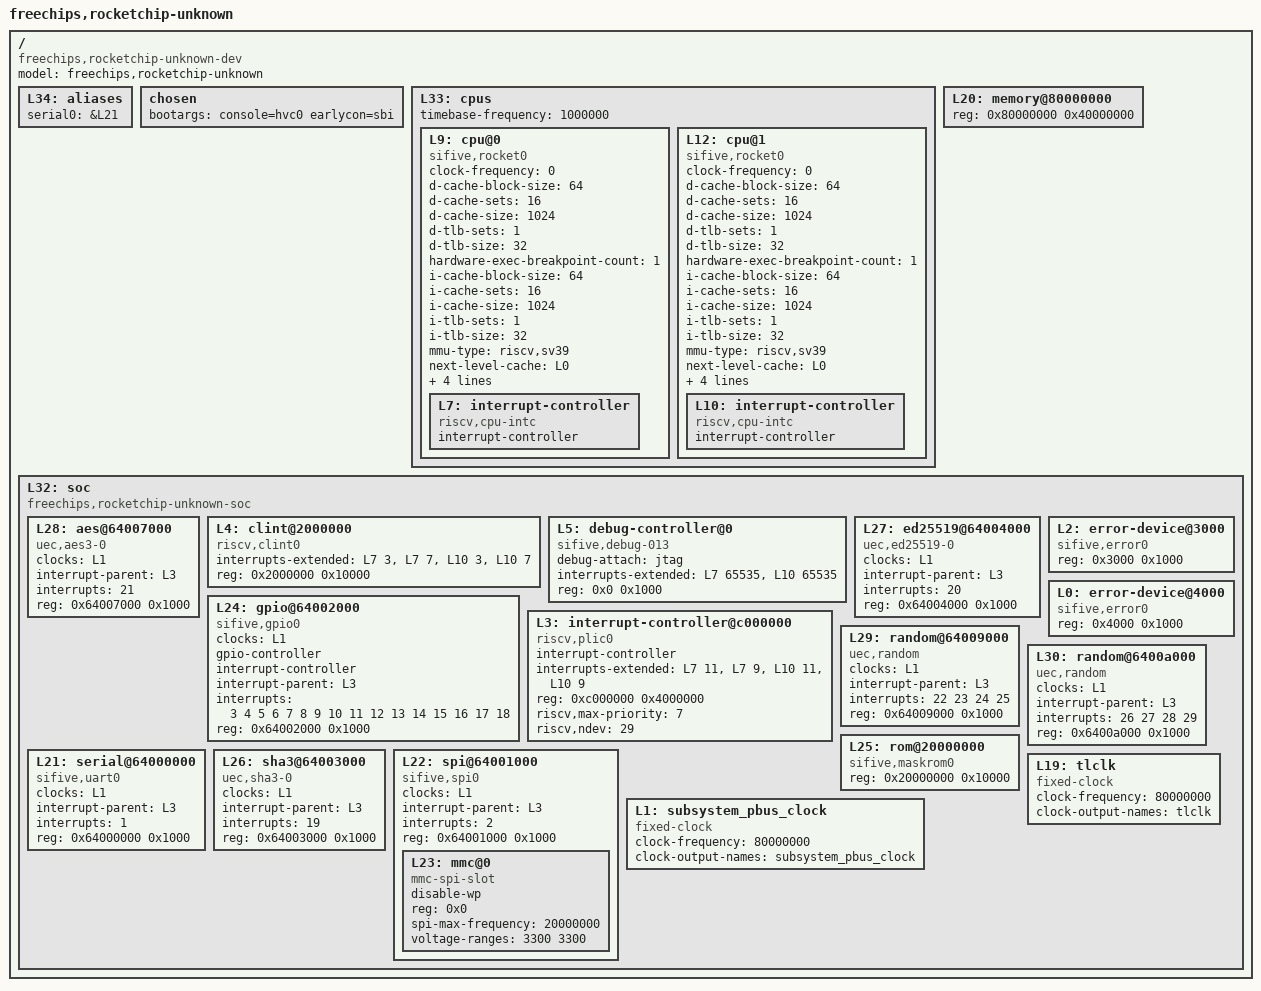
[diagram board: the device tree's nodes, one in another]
/dts-v1/;

/ {
	#address-cells = <1>;
	#size-cells = <1>;
	compatible = "freechips,rocketchip-unknown-dev";
	model = "freechips,rocketchip-unknown";
	L34: aliases {
		serial0 = &L21;
	};
	chosen {
    bootargs = "console=hvc0 earlycon=sbi";
	};
	L33: cpus {
		#address-cells = <1>;
		#size-cells = <0>;
		timebase-frequency = <1000000>;
		L9: cpu@0 {
			clock-frequency = <0>;
			compatible = "sifive,rocket0", "riscv";
			d-cache-block-size = <64>;
			d-cache-sets = <16>;
			d-cache-size = <1024>;
			d-tlb-sets = <1>;
			d-tlb-size = <32>;
			device_type = "cpu";
			hardware-exec-breakpoint-count = <1>;
			i-cache-block-size = <64>;
			i-cache-sets = <16>;
			i-cache-size = <1024>;
			i-tlb-sets = <1>;
			i-tlb-size = <32>;
			mmu-type = "riscv,sv39";
			next-level-cache = <&L0>;
			reg = <0x0>;
			riscv,isa = "rv64imafdc";
			riscv,pmpregions = <8>;
			status = "okay";
			tlb-split;
			L7: interrupt-controller {
				#interrupt-cells = <1>;
				compatible = "riscv,cpu-intc";
				interrupt-controller;
			};
		};
		L12: cpu@1 {
			clock-frequency = <0>;
			compatible = "sifive,rocket0", "riscv";
			d-cache-block-size = <64>;
			d-cache-sets = <16>;
			d-cache-size = <1024>;
			d-tlb-sets = <1>;
			d-tlb-size = <32>;
			device_type = "cpu";
			hardware-exec-breakpoint-count = <1>;
			i-cache-block-size = <64>;
			i-cache-sets = <16>;
			i-cache-size = <1024>;
			i-tlb-sets = <1>;
			i-tlb-size = <32>;
			mmu-type = "riscv,sv39";
			next-level-cache = <&L0>;
			reg = <0x1>;
			riscv,isa = "rv64imafdc";
			riscv,pmpregions = <8>;
			status = "okay";
			tlb-split;
			L10: interrupt-controller {
				#interrupt-cells = <1>;
				compatible = "riscv,cpu-intc";
				interrupt-controller;
			};
		};
	};
	L20: memory@80000000 {
		device_type = "memory";
		reg = <0x80000000 0x40000000>;
	};
	L32: soc {
		#address-cells = <1>;
		#size-cells = <1>;
		compatible = "freechips,rocketchip-unknown-soc", "simple-bus";
		ranges;
		L28: aes@64007000 {
			clocks = <&L1>;
			compatible = "uec,aes3-0";
			interrupt-parent = <&L3>;
			interrupts = <21>;
			reg = <0x64007000 0x1000>;
			reg-names = "control";
		};
		L4: clint@2000000 {
			compatible = "riscv,clint0";
			interrupts-extended = <&L7 3 &L7 7 &L10 3 &L10 7>;
			reg = <0x2000000 0x10000>;
			reg-names = "control";
		};
		L5: debug-controller@0 {
			compatible = "sifive,debug-013", "riscv,debug-013";
			debug-attach = "jtag";
			interrupts-extended = <&L7 65535 &L10 65535>;
			reg = <0x0 0x1000>;
			reg-names = "control";
		};
		L27: ed25519@64004000 {
			clocks = <&L1>;
			compatible = "uec,ed25519-0";
			interrupt-parent = <&L3>;
			interrupts = <20>;
			reg = <0x64004000 0x1000>;
			reg-names = "control";
		};
		L2: error-device@3000 {
			compatible = "sifive,error0";
			reg = <0x3000 0x1000>;
		};
		L0: error-device@4000 {
			compatible = "sifive,error0";
			reg = <0x4000 0x1000>;
		};
		L24: gpio@64002000 {
			#gpio-cells = <2>;
			#interrupt-cells = <2>;
			clocks = <&L1>;
			compatible = "sifive,gpio0", "sifive,gpio1";
			gpio-controller;
			interrupt-controller;
			interrupt-parent = <&L3>;
			interrupts = <3 4 5 6 7 8 9 10 11 12 13 14 15 16 17 18>;
			reg = <0x64002000 0x1000>;
			reg-names = "control";
		};
		L3: interrupt-controller@c000000 {
			#interrupt-cells = <1>;
			compatible = "riscv,plic0";
			interrupt-controller;
			interrupts-extended = <&L7 11 &L7 9 &L10 11 &L10 9>;
			reg = <0xc000000 0x4000000>;
			reg-names = "control";
			riscv,max-priority = <7>;
			riscv,ndev = <29>;
		};
		L29: random@64009000 {
			clocks = <&L1>;
			compatible = "uec,random";
			interrupt-parent = <&L3>;
			interrupts = <22 23 24 25>;
			reg = <0x64009000 0x1000>;
			reg-names = "control";
		};
		L30: random@6400a000 {
			clocks = <&L1>;
			compatible = "uec,random";
			interrupt-parent = <&L3>;
			interrupts = <26 27 28 29>;
			reg = <0x6400a000 0x1000>;
			reg-names = "control";
		};
		L25: rom@20000000 {
			compatible = "sifive,maskrom0";
			reg = <0x20000000 0x10000>;
			reg-names = "mem";
		};
		L21: serial@64000000 {
			clocks = <&L1>;
			compatible = "sifive,uart0";
			interrupt-parent = <&L3>;
			interrupts = <1>;
			reg = <0x64000000 0x1000>;
			reg-names = "control";
		};
		L26: sha3@64003000 {
			clocks = <&L1>;
			compatible = "uec,sha3-0";
			interrupt-parent = <&L3>;
			interrupts = <19>;
			reg = <0x64003000 0x1000>;
			reg-names = "control";
		};
		L22: spi@64001000 {
			#address-cells = <1>;
			#size-cells = <0>;
			clocks = <&L1>;
			compatible = "sifive,spi0";
			interrupt-parent = <&L3>;
			interrupts = <2>;
			reg = <0x64001000 0x1000>;
			reg-names = "control";
			L23: mmc@0 {
				compatible = "mmc-spi-slot";
				disable-wp;
				reg = <0x0>;
				spi-max-frequency = <20000000>;
				voltage-ranges = <3300 3300>;
			};
		};
		L1: subsystem_pbus_clock {
			#clock-cells = <0>;
			clock-frequency = <80000000>;
			clock-output-names = "subsystem_pbus_clock";
			compatible = "fixed-clock";
		};
		L19: tlclk {
			#clock-cells = <0>;
			clock-frequency = <80000000>;
			clock-output-names = "tlclk";
			compatible = "fixed-clock";
		};
	};
};
